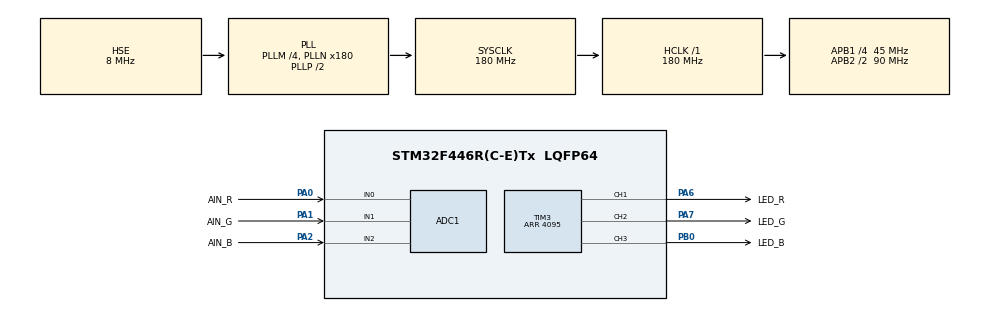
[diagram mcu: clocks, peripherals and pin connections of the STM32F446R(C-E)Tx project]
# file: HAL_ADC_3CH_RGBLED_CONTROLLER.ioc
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ADC1.Channel-0\#ChannelRegularConversion=ADC_CHANNEL_0
ADC1.Channel-1\#ChannelRegularConversion=ADC_CHANNEL_1
ADC1.Channel-3\#ChannelRegularConversion=ADC_CHANNEL_2
ADC1.ContinuousConvMode=ENABLE
ADC1.DMAContinuousRequests=ENABLE
ADC1.NbrOfConversion=3
ADC1.NbrOfConversionFlag=1
ADC1.Rank-0\#ChannelRegularConversion=1
ADC1.Rank-1\#ChannelRegularConversion=2
ADC1.Rank-3\#ChannelRegularConversion=3
ADC1.SamplingTime-0\#ChannelRegularConversion=ADC_SAMPLETIME_84CYCLES
ADC1.SamplingTime-1\#ChannelRegularConversion=ADC_SAMPLETIME_84CYCLES
ADC1.SamplingTime-3\#ChannelRegularConversion=ADC_SAMPLETIME_84CYCLES
ADC1.ScanConvMode=ENABLE
ADC1.master=1
Dma.ADC1.0.Direction=DMA_PERIPH_TO_MEMORY
Dma.ADC1.0.FIFOMode=DMA_FIFOMODE_DISABLE
Dma.ADC1.0.Instance=DMA2_Stream0
Dma.ADC1.0.MemDataAlignment=DMA_MDATAALIGN_HALFWORD
Dma.ADC1.0.MemInc=DMA_MINC_ENABLE
Dma.ADC1.0.Mode=DMA_CIRCULAR
Dma.ADC1.0.PeriphDataAlignment=DMA_PDATAALIGN_HALFWORD
Dma.ADC1.0.PeriphInc=DMA_PINC_DISABLE
Dma.ADC1.0.Priority=DMA_PRIORITY_MEDIUM
Dma.Request0=ADC1
Mcu.Family=STM32F4
Mcu.Name=STM32F446R(C-E)Tx
Mcu.Package=LQFP64
NVIC.DMA2_Stream0_IRQn=true\:0\:0\:false\:false\:true\:false\:true
NVIC.PriorityGroup=NVIC_PRIORITYGROUP_4
NVIC.TIM3_IRQn=true\:0\:0\:false\:false\:true\:true\:true
PA0-WKUP.GPIO_Label=AIN_R
PA0-WKUP.Signal=ADCx_IN0
PA1.GPIO_Label=AIN_G
PA1.Signal=ADCx_IN1
PA2.GPIO_Label=AIN_B
PA2.Signal=ADCx_IN2
PA6.GPIO_Label=LED_R
PA6.Signal=S_TIM3_CH1
PA7.GPIO_Label=LED_G
PA7.Signal=S_TIM3_CH2
PB0.GPIO_Label=LED_B
PB0.Signal=S_TIM3_CH3
PH0-OSC_IN.Mode=HSE-External-Oscillator
PH0-OSC_IN.Signal=RCC_OSC_IN
PH1-OSC_OUT.Mode=HSE-External-Oscillator
PH1-OSC_OUT.Signal=RCC_OSC_OUT
ProjectManager.HeapSize=0x200
ProjectManager.StackSize=0x400
ProjectManager.TargetToolchain=MDK-ARM V5
RCC.AHBFreq_Value=180000000
RCC.APB1CLKDivider=RCC_HCLK_DIV4
RCC.APB1Freq_Value=45000000
RCC.APB1TimFreq_Value=90000000
RCC.APB2CLKDivider=RCC_HCLK_DIV2
RCC.APB2Freq_Value=90000000
RCC.APB2TimFreq_Value=180000000
RCC.CortexFreq_Value=180000000
RCC.HCLKFreq_Value=180000000
RCC.HSE_VALUE=8000000
RCC.PLLM=4
RCC.PLLN=180
RCC.PLLSourceVirtual=RCC_PLLSOURCE_HSE
RCC.SYSCLKFreq_VALUE=180000000
RCC.SYSCLKSource=RCC_SYSCLKSOURCE_PLLCLK
RCC.USBFreq_Value=180000000
RCC.VCOOutputFreq_Value=360000000
SH.ADCx_IN0.0=ADC1_IN0,IN0
SH.ADCx_IN1.0=ADC1_IN1,IN1
SH.ADCx_IN2.0=ADC1_IN2,IN2
SH.S_TIM3_CH1.0=TIM3_CH1,PWM Generation1 CH1
SH.S_TIM3_CH2.0=TIM3_CH2,PWM Generation2 CH2
SH.S_TIM3_CH3.0=TIM3_CH3,PWM Generation3 CH3
TIM3.Channel-PWM\ Generation1\ CH1=TIM_CHANNEL_1
TIM3.Channel-PWM\ Generation2\ CH2=TIM_CHANNEL_2
TIM3.Channel-PWM\ Generation3\ CH3=TIM_CHANNEL_3
TIM3.OCPolarity_1=TIM_OCPOLARITY_LOW
TIM3.OCPolarity_2=TIM_OCPOLARITY_LOW
TIM3.OCPolarity_3=TIM_OCPOLARITY_LOW
TIM3.Period=4095
TIM3.Pulse-PWM\ Generation2\ CH2=0
VP_TIM3_VS_ClockSourceINT.Mode=Internal
board=custom

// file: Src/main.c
/* USER CODE BEGIN Header */
/**
  ******************************************************************************
  * @file           : main.c
  * @brief          : Main program body
  ******************************************************************************
  * @attention
  *
  * <h2><center>&copy; Copyright (c) 2020 STMicroelectronics.
  * All rights reserved.</center></h2>
  *
  * This software component is licensed by ST under BSD 3-Clause license,
  * the "License"; You may not use this file except in compliance with the
  * License. You may obtain a copy of the License at:
  *                        opensource.org/licenses/BSD-3-Clause
  *
  ******************************************************************************
  */
/* USER CODE END Header */

#include "main.h"

ADC_HandleTypeDef hadc1;
DMA_HandleTypeDef hdma_adc1;

TIM_HandleTypeDef htim3;

/* USER CODE BEGIN PV */
uint16_t ADC_buff[3];
/* USER CODE END PV */

void SystemClock_Config(void);
static void MX_GPIO_Init(void);
static void MX_DMA_Init(void);
static void MX_ADC1_Init(void);
static void MX_TIM3_Init(void);

/* USER CODE BEGIN 0 */

void HAL_ADC_ConvCpltCallback(ADC_HandleTypeDef* hadc)
{
  __HAL_TIM_SET_COMPARE(&htim3,TIM_CHANNEL_1,ADC_buff[0]);
	__HAL_TIM_SET_COMPARE(&htim3,TIM_CHANNEL_2,ADC_buff[1]);
	__HAL_TIM_SET_COMPARE(&htim3,TIM_CHANNEL_3,ADC_buff[2]);
}

/* USER CODE END 0 */

int main(void)
{

  /* MCU Configuration--------------------------------------------------------*/

  /* Reset of all peripherals, Initializes the Flash interface and the Systick. */
  HAL_Init();

  /* Configure the system clock */
  SystemClock_Config();

  /* Initialize all configured peripherals */
  MX_GPIO_Init();
  MX_DMA_Init();
  MX_ADC1_Init();
  MX_TIM3_Init();
  /* USER CODE BEGIN 2 */
	HAL_ADC_Start_DMA(&hadc1,(uint32_t*)ADC_buff,3);
	HAL_TIM_PWM_Start(&htim3,TIM_CHANNEL_1);
	HAL_TIM_PWM_Start(&htim3,TIM_CHANNEL_2);
	HAL_TIM_PWM_Start(&htim3,TIM_CHANNEL_3);
  /* USER CODE END 2 */

  /* Infinite loop */
  while (1)
  {

  }
}

void SystemClock_Config(void)
{
  RCC_OscInitTypeDef RCC_OscInitStruct = {0};
  RCC_ClkInitTypeDef RCC_ClkInitStruct = {0};

  /** Configure the main internal regulator output voltage
  */
  __HAL_RCC_PWR_CLK_ENABLE();
  __HAL_PWR_VOLTAGESCALING_CONFIG(PWR_REGULATOR_VOLTAGE_SCALE1);
  /** Initializes the CPU, AHB and APB busses clocks
  */
  RCC_OscInitStruct.OscillatorType = RCC_OSCILLATORTYPE_HSE;
  RCC_OscInitStruct.HSEState = RCC_HSE_ON;
  RCC_OscInitStruct.PLL.PLLState = RCC_PLL_ON;
  RCC_OscInitStruct.PLL.PLLSource = RCC_PLLSOURCE_HSE;
  RCC_OscInitStruct.PLL.PLLM = 4;
  RCC_OscInitStruct.PLL.PLLN = 180;
  RCC_OscInitStruct.PLL.PLLP = RCC_PLLP_DIV2;
  RCC_OscInitStruct.PLL.PLLQ = 2;
  RCC_OscInitStruct.PLL.PLLR = 2;
  if (HAL_RCC_OscConfig(&RCC_OscInitStruct) != HAL_OK)
  {
    Error_Handler();
  }
  /** Activate the Over-Drive mode
  */
  if (HAL_PWREx_EnableOverDrive() != HAL_OK)
  {
    Error_Handler();
  }
  /** Initializes the CPU, AHB and APB busses clocks
  */
  RCC_ClkInitStruct.ClockType = RCC_CLOCKTYPE_HCLK|RCC_CLOCKTYPE_SYSCLK
                              |RCC_CLOCKTYPE_PCLK1|RCC_CLOCKTYPE_PCLK2;
  RCC_ClkInitStruct.SYSCLKSource = RCC_SYSCLKSOURCE_PLLCLK;
  RCC_ClkInitStruct.AHBCLKDivider = RCC_SYSCLK_DIV1;
  RCC_ClkInitStruct.APB1CLKDivider = RCC_HCLK_DIV4;
  RCC_ClkInitStruct.APB2CLKDivider = RCC_HCLK_DIV2;

  if (HAL_RCC_ClockConfig(&RCC_ClkInitStruct, FLASH_LATENCY_5) != HAL_OK)
  {
    Error_Handler();
  }
}

static void MX_ADC1_Init(void)
{

  ADC_ChannelConfTypeDef sConfig = {0};

  /** Configure the global features of the ADC (Clock, Resolution, Data Alignment and number of conversion)
  */
  hadc1.Instance = ADC1;
  hadc1.Init.ClockPrescaler = ADC_CLOCK_SYNC_PCLK_DIV4;
  hadc1.Init.Resolution = ADC_RESOLUTION_12B;
  hadc1.Init.ScanConvMode = ENABLE;
  hadc1.Init.ContinuousConvMode = ENABLE;
  hadc1.Init.DiscontinuousConvMode = DISABLE;
  hadc1.Init.ExternalTrigConvEdge = ADC_EXTERNALTRIGCONVEDGE_NONE;
  hadc1.Init.ExternalTrigConv = ADC_SOFTWARE_START;
  hadc1.Init.DataAlign = ADC_DATAALIGN_RIGHT;
  hadc1.Init.NbrOfConversion = 3;
  hadc1.Init.DMAContinuousRequests = ENABLE;
  hadc1.Init.EOCSelection = ADC_EOC_SINGLE_CONV;
  if (HAL_ADC_Init(&hadc1) != HAL_OK)
  {
    Error_Handler();
  }
  /** Configure for the selected ADC regular channel its corresponding rank in the sequencer and its sample time.
  */
  sConfig.Channel = ADC_CHANNEL_0;
  sConfig.Rank = 1;
  sConfig.SamplingTime = ADC_SAMPLETIME_84CYCLES;
  if (HAL_ADC_ConfigChannel(&hadc1, &sConfig) != HAL_OK)
  {
    Error_Handler();
  }
  /** Configure for the selected ADC regular channel its corresponding rank in the sequencer and its sample time.
  */
  sConfig.Channel = ADC_CHANNEL_1;
  sConfig.Rank = 2;
  if (HAL_ADC_ConfigChannel(&hadc1, &sConfig) != HAL_OK)
  {
    Error_Handler();
  }
  /** Configure for the selected ADC regular channel its corresponding rank in the sequencer and its sample time.
  */
  sConfig.Channel = ADC_CHANNEL_2;
  sConfig.Rank = 3;
  if (HAL_ADC_ConfigChannel(&hadc1, &sConfig) != HAL_OK)
  {
    Error_Handler();
  }

}

static void MX_TIM3_Init(void)
{

  TIM_ClockConfigTypeDef sClockSourceConfig = {0};
  TIM_MasterConfigTypeDef sMasterConfig = {0};
  TIM_OC_InitTypeDef sConfigOC = {0};

  htim3.Instance = TIM3;
  htim3.Init.Prescaler = 0;
  htim3.Init.CounterMode = TIM_COUNTERMODE_UP;
  htim3.Init.Period = 4095;
  htim3.Init.ClockDivision = TIM_CLOCKDIVISION_DIV1;
  htim3.Init.AutoReloadPreload = TIM_AUTORELOAD_PRELOAD_DISABLE;
  if (HAL_TIM_Base_Init(&htim3) != HAL_OK)
  {
    Error_Handler();
  }
  sClockSourceConfig.ClockSource = TIM_CLOCKSOURCE_INTERNAL;
  if (HAL_TIM_ConfigClockSource(&htim3, &sClockSourceConfig) != HAL_OK)
  {
    Error_Handler();
  }
  if (HAL_TIM_PWM_Init(&htim3) != HAL_OK)
  {
    Error_Handler();
  }
  sMasterConfig.MasterOutputTrigger = TIM_TRGO_RESET;
  sMasterConfig.MasterSlaveMode = TIM_MASTERSLAVEMODE_DISABLE;
  if (HAL_TIMEx_MasterConfigSynchronization(&htim3, &sMasterConfig) != HAL_OK)
  {
    Error_Handler();
  }
  sConfigOC.OCMode = TIM_OCMODE_PWM1;
  sConfigOC.Pulse = 0;
  sConfigOC.OCPolarity = TIM_OCPOLARITY_LOW;
  sConfigOC.OCFastMode = TIM_OCFAST_DISABLE;
  if (HAL_TIM_PWM_ConfigChannel(&htim3, &sConfigOC, TIM_CHANNEL_1) != HAL_OK)
  {
    Error_Handler();
  }
  if (HAL_TIM_PWM_ConfigChannel(&htim3, &sConfigOC, TIM_CHANNEL_2) != HAL_OK)
  {
    Error_Handler();
  }
  if (HAL_TIM_PWM_ConfigChannel(&htim3, &sConfigOC, TIM_CHANNEL_3) != HAL_OK)
  {
    Error_Handler();
  }
  HAL_TIM_MspPostInit(&htim3);

}

static void MX_DMA_Init(void)
{

  /* DMA controller clock enable */
  __HAL_RCC_DMA2_CLK_ENABLE();

  /* DMA interrupt init */
  /* DMA2_Stream0_IRQn interrupt configuration */
  HAL_NVIC_SetPriority(DMA2_Stream0_IRQn, 0, 0);
  HAL_NVIC_EnableIRQ(DMA2_Stream0_IRQn);

}

static void MX_GPIO_Init(void)
{

  /* GPIO Ports Clock Enable */
  __HAL_RCC_GPIOH_CLK_ENABLE();
  __HAL_RCC_GPIOA_CLK_ENABLE();
  __HAL_RCC_GPIOB_CLK_ENABLE();

}

void Error_Handler(void)
{
}

/************************ (C) COPYRIGHT STMicroelectronics *****END OF FILE****/
